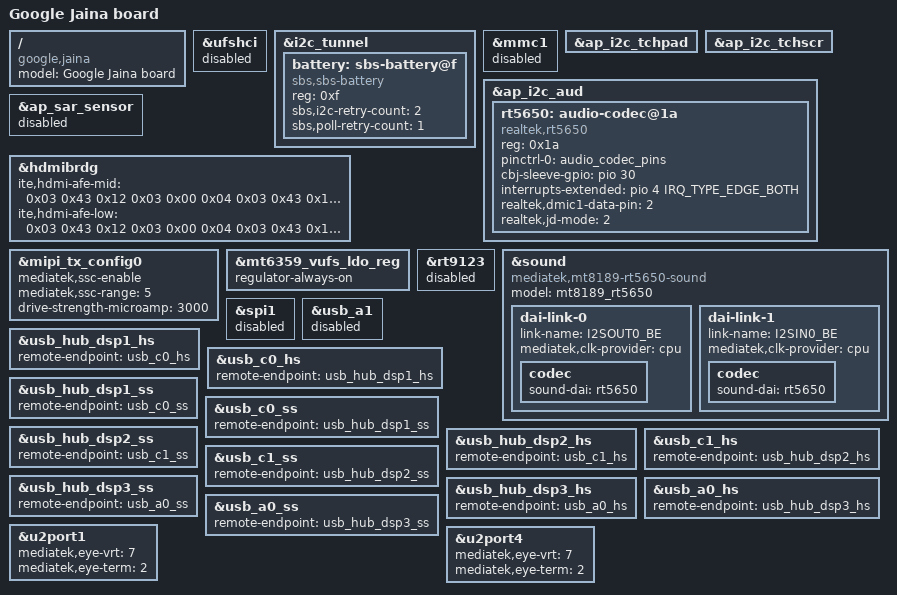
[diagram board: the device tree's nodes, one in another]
// SPDX-License-Identifier: (GPL-2.0 OR MIT)
/*
 * Copyright (C) 2025 Google Inc.
 */
/dts-v1/;
#include "mt8189-skywalker.dtsi"

/ {
	model = "Google Jaina board";
	compatible = "google,jaina", "mediatek,mt8189";
};

&ufshci {
	status = "disabled";
};

&i2c_tunnel {
	/delete-node/ sbs-battery@b;
	battery: sbs-battery@f {
		compatible = "sbs,sbs-battery";
		reg = <0xf>;
		sbs,i2c-retry-count = <2>;
		sbs,poll-retry-count = <1>;
	};
};

&mmc1 {
	status = "disabled";
};

&ap_i2c_tchpad {
	/delete-node/ trackpad@15;
};

&ap_i2c_tchscr {
	/delete-node/ touchscreen@41;
};

&ap_i2c_aud {
	/delete-node/ audio-codec@1a;

	rt5650: audio-codec@1a {
		compatible = "realtek,rt5650";
		reg = <0x1a>;
		pinctrl-names = "default";
		pinctrl-0 = <&audio_codec_pins>;
		cbj-sleeve-gpio = <&pio 30 GPIO_ACTIVE_HIGH>;
		interrupts-extended = <&pio 4 IRQ_TYPE_EDGE_BOTH>;
		#sound-dai-cells = <0>;
		realtek,dmic1-data-pin = <2>;
		realtek,jd-mode = <2>;
		status = "okay";
	};
};

&ap_sar_sensor {
	status = "disabled";
};

/* modify AFE setting */
&hdmibrdg {
	ite,hdmi-afe-mid = <
		0x03 0x43 0x12 0x03 0x00 0x04
		0x03 0x43 0x12 0x03 0x00 0x04
		0x03 0x43 0x12 0x03 0x00 0x04
		0x03 0x43 0x12 0x03 0x00 0x04
	>;

	ite,hdmi-afe-low = <
		0x03 0x43 0x12 0x03 0x00 0x04
		0x03 0x43 0x12 0x03 0x00 0x04
		0x03 0x43 0x12 0x03 0x00 0x04
		0x03 0x43 0x12 0x03 0x00 0x04
	>;
};

&mipi_tx_config0 {
	mediatek,ssc-enable;
	mediatek,ssc-range = <5>;
	drive-strength-microamp = <3000>;
};

/* &ufshci's  vccq2-supply */
&mt6359_vufs_ldo_reg {
	regulator-always-on;
};

&rt9123 {
	status = "disabled";
};

&sound {
	compatible = "mediatek,mt8189-rt5650-sound";
	model = "mt8189_rt5650";

	dai-link-0 {
		link-name = "I2SOUT0_BE";
		mediatek,clk-provider = "cpu";

		codec {
			sound-dai = <&rt5650>;
		};
	};

	dai-link-1 {
		link-name = "I2SIN0_BE";
		mediatek,clk-provider = "cpu";

		codec {
			sound-dai = <&rt5650>;
		};
	};
	/delete-node/ dai-link-2;
};

/* &spi1 is Fingerprint */
&spi1 {
	status = "disabled";
};

&usb_a1 {
	status = "disabled";
};


/* USB hub port 1 */
&usb_hub_dsp1_hs {
	remote-endpoint = <&usb_c0_hs>;
};

&usb_c0_hs {
	remote-endpoint = <&usb_hub_dsp1_hs>;
};

&usb_hub_dsp1_ss {
	remote-endpoint = <&usb_c0_ss>;
};

&usb_c0_ss {
	remote-endpoint = <&usb_hub_dsp1_ss>;
};

/* USB hub port 2 */
&usb_hub_dsp2_hs {
	remote-endpoint = <&usb_c1_hs>;
};

&usb_c1_hs {
	remote-endpoint = <&usb_hub_dsp2_hs>;
};

&usb_hub_dsp2_ss {
	remote-endpoint = <&usb_c1_ss>;
};

&usb_c1_ss {
	remote-endpoint = <&usb_hub_dsp2_ss>;
};

/* USB hub port 3 */
&usb_hub_dsp3_hs {
	remote-endpoint = <&usb_a0_hs>;
};

&usb_a0_hs {
	remote-endpoint = <&usb_hub_dsp3_hs>;
};

&usb_hub_dsp3_ss {
	remote-endpoint = <&usb_a0_ss>;
};

&usb_a0_ss {
	remote-endpoint = <&usb_hub_dsp3_ss>;
};

/* USB hub port 4 is for on-board WWAN card */

&u2port1 {
	mediatek,eye-vrt = <7>;   /* RG_USB20_VRT_VREF_SEL[14:12] */
	mediatek,eye-term = <2>;  /* RG_USB20_TERM_VERSEL[10:8] */
};

&u2port4 {
	mediatek,eye-vrt = <7>;
	mediatek,eye-term = <2>;
};
